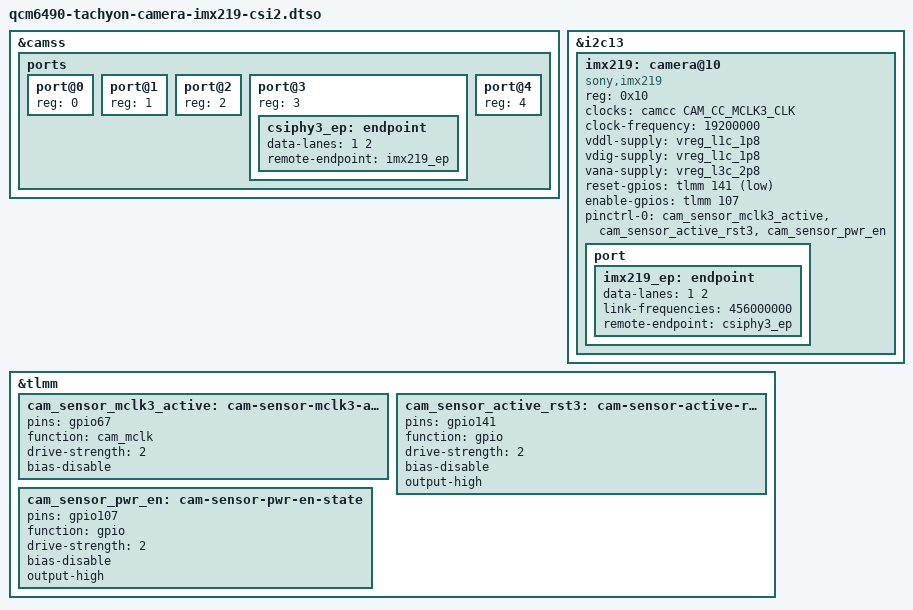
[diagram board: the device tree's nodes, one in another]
// SPDX-License-Identifier: BSD-3-Clause
/*
 * Copyright (c) 2025 Particle Industries, Inc. All rights reserved.
 */

/dts-v1/;
/plugin/;

#include <dt-bindings/gpio/gpio.h>
#include <dt-bindings/clock/qcom,camcc-sc7280.h>

&camss {
	ports {
		#address-cells = <1>;
		#size-cells = <0>;

		// CSIPHY0 - Reserved for primary camera
		port@0 {
			reg = <0>;
		};

		// CSIPHY1 - Shared with DSI
		port@1 {
			reg = <1>;
		};

		// CSIPHY2 - Available for future use
		port@2 {
			reg = <2>;
		};

		// CSIPHY3 - IMX219 camera (matches 20.04 working config)
		port@3 {
			reg = <3>;
			csiphy3_ep: endpoint {
				data-lanes = <1 2>;
				remote-endpoint = <&imx219_ep>;
			};
		};

		port@4 {
			reg = <4>;
		};
	};
};

// I2C bus for camera sensors - using I2C13 (CSI/DSI I2C Bus)
&i2c13 {
	#address-cells = <1>;
	#size-cells = <0>;

	imx219: camera@10 {
		compatible = "sony,imx219";
		reg = <0x10>;

		clocks = <&camcc CAM_CC_MCLK3_CLK>;
		clock-names = "xclk";
		clock-frequency = <19200000>;

		vddl-supply = <&vreg_l1c_1p8>;   // 1.8V digital I/O
		vdig-supply = <&vreg_l1c_1p8>;    // 1.2V digital core
		vana-supply = <&vreg_l3c_2p8>;    // 2.8V analog

		reset-gpios = <&tlmm 141 GPIO_ACTIVE_LOW>;    // Reset on GPIO141 (matches 20.04)
		enable-gpios = <&tlmm 107 GPIO_ACTIVE_HIGH>; // Enable on GPIO107 (matches 20.04)

		pinctrl-names = "default";
		pinctrl-0 = <&cam_sensor_mclk3_active &cam_sensor_active_rst3 &cam_sensor_pwr_en>;

		port {
			imx219_ep: endpoint {
				data-lanes = <1 2>;
				link-frequencies = /bits/ 64 <456000000>;
				remote-endpoint = <&csiphy3_ep>;
			};
		};
	};
};

&tlmm {
	cam_sensor_mclk3_active: cam-sensor-mclk3-active-state {
		pins = "gpio67";
		function = "cam_mclk";
		drive-strength = <2>;
		bias-disable;
	};

	cam_sensor_active_rst3: cam-sensor-active-rst3-state {
		pins = "gpio141";
		function = "gpio";
		drive-strength = <2>;
		bias-disable;
		output-high;  /* De-assert reset (active-low) */
	};

	cam_sensor_pwr_en: cam-sensor-pwr-en-state {
		pins = "gpio107";
		function = "gpio";
		drive-strength = <2>;
		bias-disable;
		output-high;  /* Enable camera power */
	};
};
